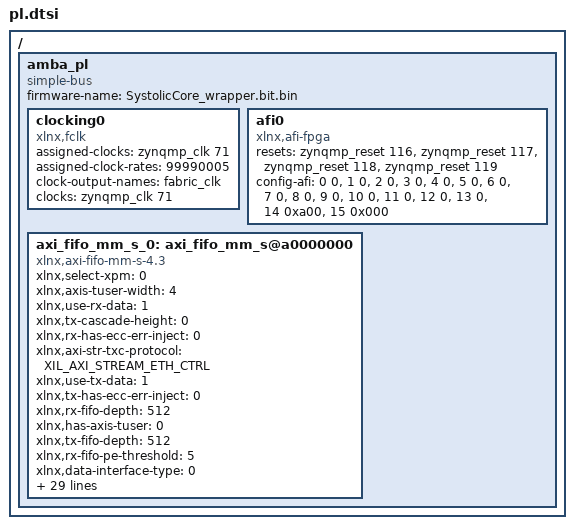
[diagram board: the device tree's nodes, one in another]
/ {
	amba_pl: amba_pl {
		ranges;
		compatible = "simple-bus";
		#address-cells = <2>;
		#size-cells = <2>;
		firmware-name = "SystolicCore_wrapper.bit.bin";
		clocking0: clocking0 {
			compatible = "xlnx,fclk";
			status = "okay";
			assigned-clocks = <&zynqmp_clk 71>;
			assigned-clock-rates = <99990005>;
			#clock-cells = <0>;
			clock-output-names = "fabric_clk";
			clocks = <&zynqmp_clk 71>;
		};
		afi0: afi0 {
			status = "okay";
			compatible = "xlnx,afi-fpga";
			resets = <&zynqmp_reset 116>, <&zynqmp_reset 117>, <&zynqmp_reset 118>, <&zynqmp_reset 119>;
			config-afi = < 0 0>, <1 0>, <2 0>, <3 0>, <4 0>, <5 0>, <6 0>, <7 0>, <8 0>, <9 0>, <10 0>, <11 0>, <12 0>, <13 0>, <14 0xa00>, <15 0x000>;
		};
		axi_fifo_mm_s_0: axi_fifo_mm_s@a0000000 {
			xlnx,select-xpm = <0>;
			xlnx,axis-tuser-width = <4>;
			compatible = "xlnx,axi-fifo-mm-s-4.3" , "xlnx,axi-fifo-mm-s";
			xlnx,use-rx-data = <1>;
			xlnx,tx-cascade-height = <0>;
			xlnx,rx-has-ecc-err-inject = <0>;
			xlnx,axi-str-txc-protocol = "XIL_AXI_STREAM_ETH_CTRL";
			xlnx,use-tx-data = <1>;
			xlnx,tx-has-ecc-err-inject = <0>;
			xlnx,rx-fifo-depth = <512>;
			xlnx,has-axis-tuser = <0>;
			xlnx,tx-fifo-depth = <512>;
			xlnx,rx-fifo-pe-threshold = <5>;
			xlnx,data-interface-type = <0>;
			xlnx,ip-name = "axi_fifo_mm_s";
			xlnx,use-tx-ctrl = <0>;
			xlnx,rx-fifo-pf-threshold = <507>;
			xlnx,axis-tid-width = <4>;
			reg = <0x0 0xa0000000 0x0 0x10000>;
			clocks = <&zynqmp_clk 71>;
			xlnx,tx-fifo-pe-threshold = <5>;
			xlnx,tx-fifo-pf-threshold = <507>;
			xlnx,s-axi4-data-width = <32>;
			xlnx,has-axis-tstrb = <0>;
			xlnx,axi-str-rxd-protocol = "XIL_AXI_STREAM_ETH_DATA";
			xlnx,use-rx-cut-through = <1>;
			xlnx,axi-str-rxd-tdata-width = <32>;
			xlnx,axis-tdest-width = <4>;
			xlnx,edk-iptype = "PERIPHERAL";
			xlnx,has-axis-tkeep = <0>;
			xlnx,has-axis-tid = <0>;
			xlnx,axi-str-txc-tdata-width = <32>;
			xlnx,axi-str-txd-protocol = "XIL_AXI_STREAM_ETH_DATA";
			xlnx,use-tx-cut-through = <1>;
			xlnx,axi-str-txd-tdata-width = <32>;
			xlnx,rx-enable-ecc = <0>;
			status = "okay";
			clock-names = "s_axi_aclk";
			xlnx,has-axis-tdest = <0>;
			xlnx,tx-enable-ecc = <0>;
			xlnx,s-axi-id-width = <4>;
			xlnx,rx-cascade-height = <0>;
			xlnx,name = "axi_fifo_mm_s_0";
		};
	};
};
